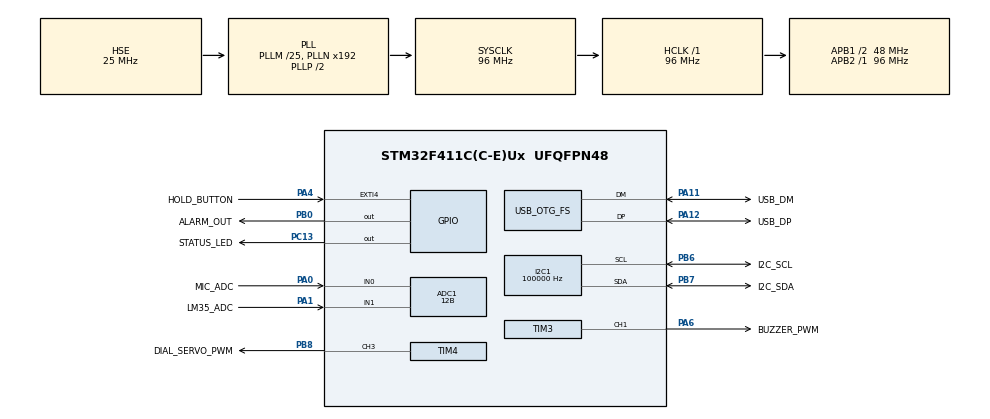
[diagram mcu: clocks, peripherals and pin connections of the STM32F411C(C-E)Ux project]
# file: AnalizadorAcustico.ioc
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ADC1.Channel-0\#ChannelRegularConversion=ADC_CHANNEL_0
ADC1.Channel-1\#ChannelRegularConversion=ADC_CHANNEL_1
ADC1.ClockPrescaler=ADC_CLOCK_SYNC_PCLK_DIV4
ADC1.ContinuousConvMode=DISABLE
ADC1.DMAContinuousRequests=ENABLE
ADC1.DataAlign=ADC_DATAALIGN_RIGHT
ADC1.DiscontinuousConvMode=DISABLE
ADC1.EOCSelection=ADC_EOC_SEQ_CONV
ADC1.ExternalTrigConv=ADC_EXTERNALTRIGCONV_T2_TRGO
ADC1.ExternalTrigConvEdge=ADC_EXTERNALTRIGCONVEDGE_RISING
ADC1.NbrOfConversion=2
ADC1.NbrOfConversionFlag=1
ADC1.Rank-0\#ChannelRegularConversion=1
ADC1.Rank-1\#ChannelRegularConversion=2
ADC1.Resolution=ADC_RESOLUTION_12B
ADC1.SamplingTime-0\#ChannelRegularConversion=ADC_SAMPLETIME_28CYCLES
ADC1.SamplingTime-1\#ChannelRegularConversion=ADC_SAMPLETIME_84CYCLES
ADC1.ScanConvMode=ENABLE
ADC1.master=1
Dma.ADC1.0.Direction=DMA_PERIPH_TO_MEMORY
Dma.ADC1.0.FIFOMode=DMA_FIFOMODE_DISABLE
Dma.ADC1.0.Instance=DMA2_Stream0
Dma.ADC1.0.MemDataAlignment=DMA_MDATAALIGN_HALFWORD
Dma.ADC1.0.MemInc=DMA_MINC_ENABLE
Dma.ADC1.0.Mode=DMA_CIRCULAR
Dma.ADC1.0.PeriphDataAlignment=DMA_PDATAALIGN_HALFWORD
Dma.ADC1.0.PeriphInc=DMA_PINC_DISABLE
Dma.ADC1.0.Priority=DMA_PRIORITY_HIGH
Dma.Request0=ADC1
I2C1.ClockSpeed=100000
Mcu.Family=STM32F4
Mcu.Name=STM32F411C(C-E)Ux
Mcu.Package=UFQFPN48
NVIC.ADC_IRQn=true\:2\:0\:true\:false\:true\:true\:true\:true
NVIC.DMA2_Stream0_IRQn=true\:1\:0\:true\:false\:true\:false\:true\:true
NVIC.EXTI4_IRQn=true\:3\:0\:true\:false\:true\:true\:true\:true
NVIC.OTG_FS_IRQn=true\:0\:0\:false\:false\:true\:true\:true\:true
NVIC.PriorityGroup=NVIC_PRIORITYGROUP_4
PA0-WKUP.GPIO_Label=MIC_ADC
PA0-WKUP.Signal=ADCx_IN0
PA1.GPIO_Label=LM35_ADC
PA1.Signal=ADCx_IN1
PA11.GPIO_Label=USB_DM
PA11.Mode=Device_Only
PA11.Signal=USB_OTG_FS_DM
PA12.GPIO_Label=USB_DP
PA12.Mode=Device_Only
PA12.Signal=USB_OTG_FS_DP
PA13.GPIO_Label=SWDIO
PA13.Mode=Serial_Wire
PA13.Signal=SYS_JTMS-SWDIO
PA14.GPIO_Label=SWCLK
PA14.Mode=Serial_Wire
PA14.Signal=SYS_JTCK-SWCLK
PA4.GPIO_Label=HOLD_BUTTON
PA4.GPIO_ModeDefaultEXTI=GPIO_MODE_IT_FALLING
PA4.GPIO_PuPd=GPIO_PULLUP
PA4.Signal=GPXTI4
PA6.GPIO_Label=BUZZER_PWM
PA6.Signal=S_TIM3_CH1
PB0.GPIO_Label=ALARM_OUT
PB0.PinState=GPIO_PIN_RESET
PB0.Signal=GPIO_Output
PB6.GPIO_Label=I2C_SCL
PB6.Mode=I2C
PB6.Signal=I2C1_SCL
PB7.GPIO_Label=I2C_SDA
PB7.Mode=I2C
PB7.Signal=I2C1_SDA
PB8.GPIO_Label=DIAL_SERVO_PWM
PB8.Signal=S_TIM4_CH3
PC13-ANTI_TAMP.GPIO_Label=STATUS_LED
PC13-ANTI_TAMP.PinState=GPIO_PIN_SET
PC13-ANTI_TAMP.Signal=GPIO_Output
PH0\ -\ OSC_IN.GPIO_Label=HSE_IN
PH0\ -\ OSC_IN.Mode=HSE-External-Oscillator
PH0\ -\ OSC_IN.Signal=RCC_OSC_IN
PH1\ -\ OSC_OUT.GPIO_Label=HSE_OUT
PH1\ -\ OSC_OUT.Mode=HSE-External-Oscillator
PH1\ -\ OSC_OUT.Signal=RCC_OSC_OUT
ProjectManager.HeapSize=0x200
ProjectManager.StackSize=0x400
ProjectManager.TargetToolchain=STM32CubeIDE
RCC.48MHZClocksFreq_Value=48000000
RCC.AHBFreq_Value=96000000
RCC.APB1CLKDivider=RCC_HCLK_DIV2
RCC.APB1Freq_Value=48000000
RCC.APB1TimFreq_Value=96000000
RCC.APB2Freq_Value=96000000
RCC.APB2TimFreq_Value=96000000
RCC.CortexFreq_Value=96000000
RCC.HCLKFreq_Value=96000000
RCC.HSE_VALUE=25000000
RCC.HSI_VALUE=16000000
RCC.LSE_VALUE=32768
RCC.PLLM=25
RCC.PLLN=192
RCC.SYSCLKFreq_VALUE=96000000
RCC.SYSCLKSource=RCC_SYSCLKSOURCE_PLLCLK
RCC.VCOOutputFreq_Value=192000000
SH.ADCx_IN0.0=ADC1_IN0,IN0
SH.ADCx_IN1.0=ADC1_IN1,IN1
SH.S_TIM3_CH1.0=TIM3_CH1,PWM Generation1 CH1
SH.S_TIM4_CH3.0=TIM4_CH3,PWM Generation3 CH3
TIM2.Period=9599
TIM2.Prescaler=0
TIM2.TIM_MasterOutputTrigger=TIM_TRGO_UPDATE
TIM3.AutoReloadPreload=TIM_AUTORELOAD_PRELOAD_ENABLE
TIM3.Channel-PWM\ Generation1\ CH1=TIM_CHANNEL_1
TIM3.Period=999
TIM3.Prescaler=95
TIM3.Pulse-PWM\ Generation1\ CH1=0
TIM4.AutoReloadPreload=TIM_AUTORELOAD_PRELOAD_ENABLE
TIM4.Channel-PWM\ Generation3\ CH3=TIM_CHANNEL_3
TIM4.Period=19999
TIM4.Prescaler=95
TIM4.Pulse-PWM\ Generation3\ CH3=1500
USB_DEVICE.CLASS_NAME_FS=CDC
USB_DEVICE.USBD_SELF_POWERED=0
USB_DEVICE.VirtualMode=Cdc
USB_DEVICE.VirtualModeFS=Cdc_FS
USB_OTG_FS.VirtualMode=Device_Only
USB_OTG_FS.vbus_sensing_enable=DISABLE
VP_TIM2_VS_ClockSourceINT.Mode=Internal
VP_TIM3_VS_ClockSourceINT.Mode=Internal
VP_TIM4_VS_ClockSourceINT.Mode=Internal
VP_USB_DEVICE_VS_USB_DEVICE_CDC_FS.Mode=CDC_FS
board=custom

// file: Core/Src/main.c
/* USER CODE BEGIN Header */
/**
  ******************************************************************************
  * @file           : main.c
  * @brief          : Main program body
  ******************************************************************************
  * @attention
  *
  * Copyright (c) 2026 STMicroelectronics.
  * All rights reserved.
  *
  * This software is licensed under terms that can be found in the LICENSE file
  * in the root directory of this software component.
  * If no LICENSE file comes with this software, it is provided AS-IS.
  *
  ******************************************************************************
  */
/* USER CODE END Header */
#include "main.h"
#include "usb_device.h"

/* USER CODE BEGIN Includes */
#include "app_main.h"
/* USER CODE END Includes */

ADC_HandleTypeDef hadc1;
DMA_HandleTypeDef hdma_adc1;

I2C_HandleTypeDef hi2c1;

TIM_HandleTypeDef htim2;
TIM_HandleTypeDef htim3;
TIM_HandleTypeDef htim4;

void SystemClock_Config(void);
static void MX_GPIO_Init(void);
static void MX_DMA_Init(void);
static void MX_ADC1_Init(void);
static void MX_I2C1_Init(void);
static void MX_TIM2_Init(void);
static void MX_TIM3_Init(void);
static void MX_TIM4_Init(void);

int main(void)
{

  /* MCU Configuration--------------------------------------------------------*/

  /* Reset of all peripherals, Initializes the Flash interface and the Systick. */
  HAL_Init();

  /* Configure the system clock */
  SystemClock_Config();

  /* Initialize all configured peripherals */
  MX_GPIO_Init();
  MX_DMA_Init();
  MX_ADC1_Init();
  MX_I2C1_Init();
  MX_TIM2_Init();
  MX_TIM3_Init();
  MX_TIM4_Init();
  MX_USB_DEVICE_Init();
  /* USER CODE BEGIN 2 */
  App_Iniciar();
  /* USER CODE END 2 */

  /* Infinite loop */
  while (1)
  {

    /* USER CODE BEGIN 3 */
    App_Procesar();
  }
  /* USER CODE END 3 */
}

void SystemClock_Config(void)
{
  RCC_OscInitTypeDef RCC_OscInitStruct = {0};
  RCC_ClkInitTypeDef RCC_ClkInitStruct = {0};

  /** Configure the main internal regulator output voltage
  */
  __HAL_RCC_PWR_CLK_ENABLE();
  __HAL_PWR_VOLTAGESCALING_CONFIG(PWR_REGULATOR_VOLTAGE_SCALE1);

  /** Initializes the RCC Oscillators according to the specified parameters
  * in the RCC_OscInitTypeDef structure.
  */
  RCC_OscInitStruct.OscillatorType = RCC_OSCILLATORTYPE_HSE;
  RCC_OscInitStruct.HSEState = RCC_HSE_ON;
  RCC_OscInitStruct.PLL.PLLState = RCC_PLL_ON;
  RCC_OscInitStruct.PLL.PLLSource = RCC_PLLSOURCE_HSE;
  RCC_OscInitStruct.PLL.PLLM = 25;
  RCC_OscInitStruct.PLL.PLLN = 192;
  RCC_OscInitStruct.PLL.PLLP = RCC_PLLP_DIV2;
  RCC_OscInitStruct.PLL.PLLQ = 4;
  if (HAL_RCC_OscConfig(&RCC_OscInitStruct) != HAL_OK)
  {
    Error_Handler();
  }

  /** Initializes the CPU, AHB and APB buses clocks
  */
  RCC_ClkInitStruct.ClockType = RCC_CLOCKTYPE_HCLK|RCC_CLOCKTYPE_SYSCLK
                              |RCC_CLOCKTYPE_PCLK1|RCC_CLOCKTYPE_PCLK2;
  RCC_ClkInitStruct.SYSCLKSource = RCC_SYSCLKSOURCE_PLLCLK;
  RCC_ClkInitStruct.AHBCLKDivider = RCC_SYSCLK_DIV1;
  RCC_ClkInitStruct.APB1CLKDivider = RCC_HCLK_DIV2;
  RCC_ClkInitStruct.APB2CLKDivider = RCC_HCLK_DIV1;

  if (HAL_RCC_ClockConfig(&RCC_ClkInitStruct, FLASH_LATENCY_3) != HAL_OK)
  {
    Error_Handler();
  }
}

static void MX_ADC1_Init(void)
{

  ADC_ChannelConfTypeDef sConfig = {0};

  /** Configure the global features of the ADC (Clock, Resolution, Data Alignment and number of conversion)
  */
  hadc1.Instance = ADC1;
  hadc1.Init.ClockPrescaler = ADC_CLOCK_SYNC_PCLK_DIV4;
  hadc1.Init.Resolution = ADC_RESOLUTION_12B;
  hadc1.Init.ScanConvMode = ENABLE;
  hadc1.Init.ContinuousConvMode = DISABLE;
  hadc1.Init.DiscontinuousConvMode = DISABLE;
  hadc1.Init.ExternalTrigConvEdge = ADC_EXTERNALTRIGCONVEDGE_RISING;
  hadc1.Init.ExternalTrigConv = ADC_EXTERNALTRIGCONV_T2_TRGO;
  hadc1.Init.DataAlign = ADC_DATAALIGN_RIGHT;
  hadc1.Init.NbrOfConversion = 2;
  hadc1.Init.DMAContinuousRequests = ENABLE;
  hadc1.Init.EOCSelection = ADC_EOC_SEQ_CONV;
  if (HAL_ADC_Init(&hadc1) != HAL_OK)
  {
    Error_Handler();
  }

  /** Configure for the selected ADC regular channel its corresponding rank in the sequencer and its sample time.
  */
  sConfig.Channel = ADC_CHANNEL_0;
  sConfig.Rank = 1;
  sConfig.SamplingTime = ADC_SAMPLETIME_28CYCLES;
  if (HAL_ADC_ConfigChannel(&hadc1, &sConfig) != HAL_OK)
  {
    Error_Handler();
  }

  /** Configure for the selected ADC regular channel its corresponding rank in the sequencer and its sample time.
  */
  sConfig.Channel = ADC_CHANNEL_1;
  sConfig.Rank = 2;
  sConfig.SamplingTime = ADC_SAMPLETIME_84CYCLES;
  if (HAL_ADC_ConfigChannel(&hadc1, &sConfig) != HAL_OK)
  {
    Error_Handler();
  }

}

static void MX_I2C1_Init(void)
{

  hi2c1.Instance = I2C1;
  hi2c1.Init.ClockSpeed = 100000;
  hi2c1.Init.DutyCycle = I2C_DUTYCYCLE_2;
  hi2c1.Init.OwnAddress1 = 0;
  hi2c1.Init.AddressingMode = I2C_ADDRESSINGMODE_7BIT;
  hi2c1.Init.DualAddressMode = I2C_DUALADDRESS_DISABLE;
  hi2c1.Init.OwnAddress2 = 0;
  hi2c1.Init.GeneralCallMode = I2C_GENERALCALL_DISABLE;
  hi2c1.Init.NoStretchMode = I2C_NOSTRETCH_DISABLE;
  if (HAL_I2C_Init(&hi2c1) != HAL_OK)
  {
    Error_Handler();
  }

}

static void MX_TIM2_Init(void)
{

  TIM_ClockConfigTypeDef sClockSourceConfig = {0};
  TIM_MasterConfigTypeDef sMasterConfig = {0};

  htim2.Instance = TIM2;
  htim2.Init.Prescaler = 0;
  htim2.Init.CounterMode = TIM_COUNTERMODE_UP;
  htim2.Init.Period = 9599;
  htim2.Init.ClockDivision = TIM_CLOCKDIVISION_DIV1;
  htim2.Init.AutoReloadPreload = TIM_AUTORELOAD_PRELOAD_DISABLE;
  if (HAL_TIM_Base_Init(&htim2) != HAL_OK)
  {
    Error_Handler();
  }
  sClockSourceConfig.ClockSource = TIM_CLOCKSOURCE_INTERNAL;
  if (HAL_TIM_ConfigClockSource(&htim2, &sClockSourceConfig) != HAL_OK)
  {
    Error_Handler();
  }
  sMasterConfig.MasterOutputTrigger = TIM_TRGO_UPDATE;
  sMasterConfig.MasterSlaveMode = TIM_MASTERSLAVEMODE_DISABLE;
  if (HAL_TIMEx_MasterConfigSynchronization(&htim2, &sMasterConfig) != HAL_OK)
  {
    Error_Handler();
  }

}

static void MX_TIM3_Init(void)
{

  TIM_ClockConfigTypeDef sClockSourceConfig = {0};
  TIM_MasterConfigTypeDef sMasterConfig = {0};
  TIM_OC_InitTypeDef sConfigOC = {0};

  htim3.Instance = TIM3;
  htim3.Init.Prescaler = 95;
  htim3.Init.CounterMode = TIM_COUNTERMODE_UP;
  htim3.Init.Period = 999;
  htim3.Init.ClockDivision = TIM_CLOCKDIVISION_DIV1;
  htim3.Init.AutoReloadPreload = TIM_AUTORELOAD_PRELOAD_ENABLE;
  if (HAL_TIM_Base_Init(&htim3) != HAL_OK)
  {
    Error_Handler();
  }
  sClockSourceConfig.ClockSource = TIM_CLOCKSOURCE_INTERNAL;
  if (HAL_TIM_ConfigClockSource(&htim3, &sClockSourceConfig) != HAL_OK)
  {
    Error_Handler();
  }
  if (HAL_TIM_PWM_Init(&htim3) != HAL_OK)
  {
    Error_Handler();
  }
  sMasterConfig.MasterOutputTrigger = TIM_TRGO_RESET;
  sMasterConfig.MasterSlaveMode = TIM_MASTERSLAVEMODE_DISABLE;
  if (HAL_TIMEx_MasterConfigSynchronization(&htim3, &sMasterConfig) != HAL_OK)
  {
    Error_Handler();
  }
  sConfigOC.OCMode = TIM_OCMODE_PWM1;
  sConfigOC.Pulse = 0;
  sConfigOC.OCPolarity = TIM_OCPOLARITY_HIGH;
  sConfigOC.OCFastMode = TIM_OCFAST_DISABLE;
  if (HAL_TIM_PWM_ConfigChannel(&htim3, &sConfigOC, TIM_CHANNEL_1) != HAL_OK)
  {
    Error_Handler();
  }
  HAL_TIM_MspPostInit(&htim3);

}

static void MX_TIM4_Init(void)
{

  TIM_ClockConfigTypeDef sClockSourceConfig = {0};
  TIM_MasterConfigTypeDef sMasterConfig = {0};
  TIM_OC_InitTypeDef sConfigOC = {0};

  htim4.Instance = TIM4;
  htim4.Init.Prescaler = 95;
  htim4.Init.CounterMode = TIM_COUNTERMODE_UP;
  htim4.Init.Period = 19999;
  htim4.Init.ClockDivision = TIM_CLOCKDIVISION_DIV1;
  htim4.Init.AutoReloadPreload = TIM_AUTORELOAD_PRELOAD_ENABLE;
  if (HAL_TIM_Base_Init(&htim4) != HAL_OK)
  {
    Error_Handler();
  }
  sClockSourceConfig.ClockSource = TIM_CLOCKSOURCE_INTERNAL;
  if (HAL_TIM_ConfigClockSource(&htim4, &sClockSourceConfig) != HAL_OK)
  {
    Error_Handler();
  }
  if (HAL_TIM_PWM_Init(&htim4) != HAL_OK)
  {
    Error_Handler();
  }
  sMasterConfig.MasterOutputTrigger = TIM_TRGO_RESET;
  sMasterConfig.MasterSlaveMode = TIM_MASTERSLAVEMODE_DISABLE;
  if (HAL_TIMEx_MasterConfigSynchronization(&htim4, &sMasterConfig) != HAL_OK)
  {
    Error_Handler();
  }
  sConfigOC.OCMode = TIM_OCMODE_PWM1;
  sConfigOC.Pulse = 1500;
  sConfigOC.OCPolarity = TIM_OCPOLARITY_HIGH;
  sConfigOC.OCFastMode = TIM_OCFAST_DISABLE;
  if (HAL_TIM_PWM_ConfigChannel(&htim4, &sConfigOC, TIM_CHANNEL_3) != HAL_OK)
  {
    Error_Handler();
  }
  HAL_TIM_MspPostInit(&htim4);

}

static void MX_DMA_Init(void)
{

  /* DMA controller clock enable */
  __HAL_RCC_DMA2_CLK_ENABLE();

  /* DMA interrupt init */
  /* DMA2_Stream0_IRQn interrupt configuration */
  HAL_NVIC_SetPriority(DMA2_Stream0_IRQn, 1, 0);
  HAL_NVIC_EnableIRQ(DMA2_Stream0_IRQn);

}

static void MX_GPIO_Init(void)
{
  GPIO_InitTypeDef GPIO_InitStruct = {0};

  /* GPIO Ports Clock Enable */
  __HAL_RCC_GPIOC_CLK_ENABLE();
  __HAL_RCC_GPIOH_CLK_ENABLE();
  __HAL_RCC_GPIOA_CLK_ENABLE();
  __HAL_RCC_GPIOB_CLK_ENABLE();

  /*Configure GPIO pin Output Level */
  HAL_GPIO_WritePin(STATUS_LED_GPIO_Port, STATUS_LED_Pin, GPIO_PIN_SET);

  /*Configure GPIO pin Output Level */
  HAL_GPIO_WritePin(ALARM_OUT_GPIO_Port, ALARM_OUT_Pin, GPIO_PIN_RESET);

  /*Configure GPIO pin : STATUS_LED_Pin */
  GPIO_InitStruct.Pin = STATUS_LED_Pin;
  GPIO_InitStruct.Mode = GPIO_MODE_OUTPUT_PP;
  GPIO_InitStruct.Pull = GPIO_NOPULL;
  GPIO_InitStruct.Speed = GPIO_SPEED_FREQ_LOW;
  HAL_GPIO_Init(STATUS_LED_GPIO_Port, &GPIO_InitStruct);

  /*Configure GPIO pin : HOLD_BUTTON_Pin */
  GPIO_InitStruct.Pin = HOLD_BUTTON_Pin;
  GPIO_InitStruct.Mode = GPIO_MODE_IT_FALLING;
  GPIO_InitStruct.Pull = GPIO_PULLUP;
  HAL_GPIO_Init(HOLD_BUTTON_GPIO_Port, &GPIO_InitStruct);

  /*Configure GPIO pin : ALARM_OUT_Pin */
  GPIO_InitStruct.Pin = ALARM_OUT_Pin;
  GPIO_InitStruct.Mode = GPIO_MODE_OUTPUT_PP;
  GPIO_InitStruct.Pull = GPIO_NOPULL;
  GPIO_InitStruct.Speed = GPIO_SPEED_FREQ_LOW;
  HAL_GPIO_Init(ALARM_OUT_GPIO_Port, &GPIO_InitStruct);

  /* EXTI interrupt init*/
  HAL_NVIC_SetPriority(EXTI4_IRQn, 3, 0);
  HAL_NVIC_EnableIRQ(EXTI4_IRQn);

}

void Error_Handler(void)
{
  __disable_irq();
  while (1)
  {
  }
}
